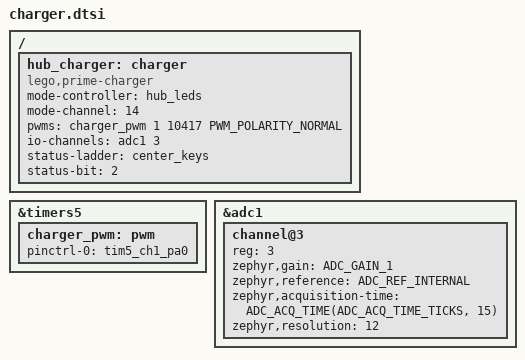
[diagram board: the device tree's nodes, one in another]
// SPDX-License-Identifier: Apache-2.0
/ {
	hub_charger: charger {
		compatible = "lego,prime-charger";
		mode-controller = <&hub_leds>;
		mode-channel = <14>;
		pwms = <&charger_pwm 1 10417 PWM_POLARITY_NORMAL>;
		io-channels = <&adc1 3>;
		status-ladder = <&center_keys>;
		status-bit = <2>;
	};
};

&timers5 {
	status = "okay";
	charger_pwm: pwm {
		pinctrl-0 = <&tim5_ch1_pa0>;
		pinctrl-names = "default";
		status = "okay";
	};
};

&adc1 {
	channel@3 {
		reg = <3>;
		zephyr,gain = "ADC_GAIN_1";
		zephyr,reference = "ADC_REF_INTERNAL";
		zephyr,acquisition-time = <ADC_ACQ_TIME(ADC_ACQ_TIME_TICKS, 15)>;
		zephyr,resolution = <12>;
	};
};
